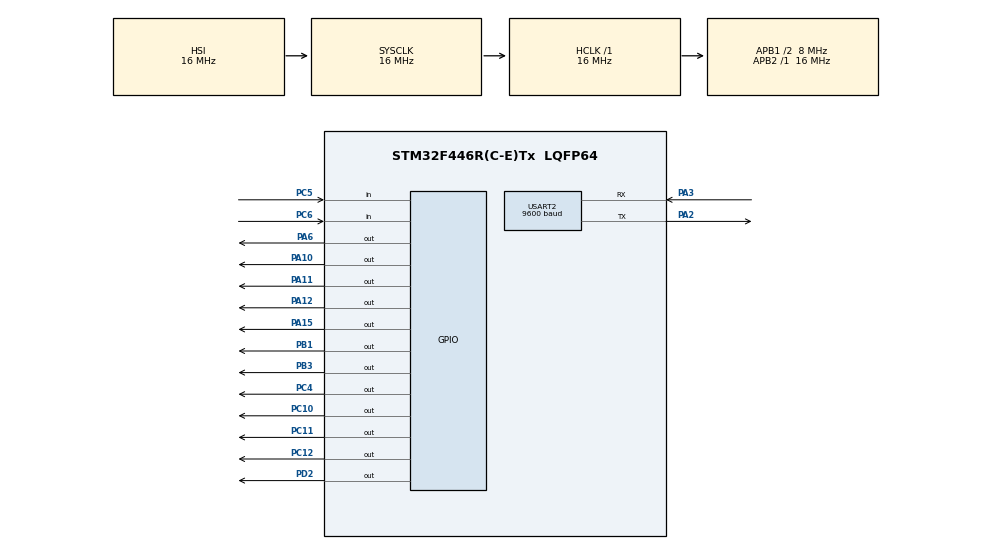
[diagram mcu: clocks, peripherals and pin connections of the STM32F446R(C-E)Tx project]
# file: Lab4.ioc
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Dma.Request0=USART2_RX
Dma.Request1=USART2_TX
Dma.USART2_RX.0.Direction=DMA_PERIPH_TO_MEMORY
Dma.USART2_RX.0.FIFOMode=DMA_FIFOMODE_DISABLE
Dma.USART2_RX.0.Instance=DMA1_Stream5
Dma.USART2_RX.0.MemDataAlignment=DMA_MDATAALIGN_BYTE
Dma.USART2_RX.0.MemInc=DMA_MINC_ENABLE
Dma.USART2_RX.0.Mode=DMA_CIRCULAR
Dma.USART2_RX.0.PeriphDataAlignment=DMA_PDATAALIGN_BYTE
Dma.USART2_RX.0.PeriphInc=DMA_PINC_DISABLE
Dma.USART2_RX.0.Priority=DMA_PRIORITY_VERY_HIGH
Dma.USART2_TX.1.Direction=DMA_MEMORY_TO_PERIPH
Dma.USART2_TX.1.FIFOMode=DMA_FIFOMODE_DISABLE
Dma.USART2_TX.1.Instance=DMA1_Stream6
Dma.USART2_TX.1.MemDataAlignment=DMA_MDATAALIGN_BYTE
Dma.USART2_TX.1.MemInc=DMA_MINC_ENABLE
Dma.USART2_TX.1.Mode=DMA_NORMAL
Dma.USART2_TX.1.PeriphDataAlignment=DMA_PDATAALIGN_BYTE
Dma.USART2_TX.1.PeriphInc=DMA_PINC_DISABLE
Dma.USART2_TX.1.Priority=DMA_PRIORITY_HIGH
Mcu.Family=STM32F4
Mcu.Name=STM32F446R(C-E)Tx
Mcu.Package=LQFP64
NVIC.DMA1_Stream5_IRQn=true\:0\:0\:false\:false\:true\:false\:true\:true
NVIC.DMA1_Stream6_IRQn=true\:0\:0\:false\:false\:true\:false\:true\:true
NVIC.PriorityGroup=NVIC_PRIORITYGROUP_4
NVIC.TIM2_IRQn=true\:0\:0\:false\:false\:true\:true\:true\:true
PA10.Signal=GPIO_Output
PA11.Signal=GPIO_Output
PA12.Signal=GPIO_Output
PA15.Signal=GPIO_Output
PA2.Mode=Asynchronous
PA2.Signal=USART2_TX
PA3.Mode=Asynchronous
PA3.Signal=USART2_RX
PA6.Signal=GPIO_Output
PB1.Signal=GPIO_Output
PB3.Signal=GPIO_Output
PC10.Signal=GPIO_Output
PC11.Signal=GPIO_Output
PC12.Signal=GPIO_Output
PC4.Signal=GPIO_Output
PC5.Signal=GPIO_Input
PC6.Signal=GPIO_Input
PD2.Signal=GPIO_Output
PH0-OSC_IN.Mode=HSE-External-Oscillator
PH0-OSC_IN.Signal=RCC_OSC_IN
PH1-OSC_OUT.Mode=HSE-External-Oscillator
PH1-OSC_OUT.Signal=RCC_OSC_OUT
ProjectManager.HeapSize=0x200
ProjectManager.StackSize=0x400
ProjectManager.TargetToolchain=STM32CubeIDE
RCC.AHBFreq_Value=16000000
RCC.APB1CLKDivider=RCC_HCLK_DIV2
RCC.APB1Freq_Value=8000000
RCC.APB1TimFreq_Value=16000000
RCC.APB2Freq_Value=16000000
RCC.APB2TimFreq_Value=16000000
RCC.CortexFreq_Value=16000000
RCC.HCLKFreq_Value=16000000
RCC.HSE_VALUE=25000000
RCC.PLLM=8
RCC.PLLN=50
RCC.SYSCLKFreq_VALUE=16000000
RCC.USBFreq_Value=50000000
RCC.VCOOutputFreq_Value=100000000
TIM2.Period=10000
TIM2.Prescaler=15
USART2.BaudRate=9600
USART2.VirtualMode=VM_ASYNC
VP_TIM2_VS_ClockSourceINT.Mode=Internal
board=custom

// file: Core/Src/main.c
/* USER CODE BEGIN Header */
/**
  ******************************************************************************
  * @file           : main.c
  * @brief          : Main program body
  ******************************************************************************
  * @attention
  *
  * Copyright (c) 2022 STMicroelectronics.
  * All rights reserved.
  *
  * This software is licensed under terms that can be found in the LICENSE file
  * in the root directory of this software component.
  * If no LICENSE file comes with this software, it is provided AS-IS.
  *
  ******************************************************************************
  */
/* USER CODE END Header */
#include "main.h"

TIM_HandleTypeDef htim2;

UART_HandleTypeDef huart2;
DMA_HandleTypeDef hdma_usart2_rx;
DMA_HandleTypeDef hdma_usart2_tx;

void SystemClock_Config(void);
static void MX_GPIO_Init(void);
static void MX_DMA_Init(void);
static void MX_USART2_UART_Init(void);
static void MX_TIM2_Init(void);

/* USER CODE BEGIN 0 */
float fcn(float x) {
	return x;
}

float buf[8] = {0};
int offset = 0;
void HAL_TIM_PeriodElapsedCallback(TIM_HandleTypeDef* htim) {
	HAL_UART_Transmit_DMA(&huart2, (uint8_t*)&buf[offset], sizeof(float));
	offset = (offset + 4) % 8;
}
/* USER CODE END 0 */

int main(void)
{

  /* MCU Configuration--------------------------------------------------------*/

  /* Reset of all peripherals, Initializes the Flash interface and the Systick. */
  HAL_Init();

  /* Configure the system clock */
  SystemClock_Config();

  /* Initialize all configured peripherals */
  MX_GPIO_Init();
  MX_DMA_Init();
  MX_USART2_UART_Init();
  MX_TIM2_Init();
  /* USER CODE BEGIN 2 */

  HAL_TIM_Base_Start_IT(&htim2);
  HAL_UART_Receive_DMA(&huart2, (uint8_t*)&buf, 8);

  /* USER CODE END 2 */

  /* Infinite loop */
  while (1)
  {

  }
}

void SystemClock_Config(void)
{
  RCC_OscInitTypeDef RCC_OscInitStruct = {0};
  RCC_ClkInitTypeDef RCC_ClkInitStruct = {0};

  /** Configure the main internal regulator output voltage
  */
  __HAL_RCC_PWR_CLK_ENABLE();
  __HAL_PWR_VOLTAGESCALING_CONFIG(PWR_REGULATOR_VOLTAGE_SCALE3);

  /** Initializes the RCC Oscillators according to the specified parameters
  * in the RCC_OscInitTypeDef structure.
  */
  RCC_OscInitStruct.OscillatorType = RCC_OSCILLATORTYPE_HSI;
  RCC_OscInitStruct.HSIState = RCC_HSI_ON;
  RCC_OscInitStruct.HSICalibrationValue = RCC_HSICALIBRATION_DEFAULT;
  RCC_OscInitStruct.PLL.PLLState = RCC_PLL_NONE;
  if (HAL_RCC_OscConfig(&RCC_OscInitStruct) != HAL_OK)
  {
    Error_Handler();
  }

  /** Initializes the CPU, AHB and APB buses clocks
  */
  RCC_ClkInitStruct.ClockType = RCC_CLOCKTYPE_HCLK|RCC_CLOCKTYPE_SYSCLK
                              |RCC_CLOCKTYPE_PCLK1|RCC_CLOCKTYPE_PCLK2;
  RCC_ClkInitStruct.SYSCLKSource = RCC_SYSCLKSOURCE_HSI;
  RCC_ClkInitStruct.AHBCLKDivider = RCC_SYSCLK_DIV1;
  RCC_ClkInitStruct.APB1CLKDivider = RCC_HCLK_DIV2;
  RCC_ClkInitStruct.APB2CLKDivider = RCC_HCLK_DIV1;

  if (HAL_RCC_ClockConfig(&RCC_ClkInitStruct, FLASH_LATENCY_0) != HAL_OK)
  {
    Error_Handler();
  }
}

static void MX_TIM2_Init(void)
{

  TIM_ClockConfigTypeDef sClockSourceConfig = {0};
  TIM_MasterConfigTypeDef sMasterConfig = {0};

  htim2.Instance = TIM2;
  htim2.Init.Prescaler = 15;
  htim2.Init.CounterMode = TIM_COUNTERMODE_UP;
  htim2.Init.Period = 10000;
  htim2.Init.ClockDivision = TIM_CLOCKDIVISION_DIV1;
  htim2.Init.AutoReloadPreload = TIM_AUTORELOAD_PRELOAD_DISABLE;
  if (HAL_TIM_Base_Init(&htim2) != HAL_OK)
  {
    Error_Handler();
  }
  sClockSourceConfig.ClockSource = TIM_CLOCKSOURCE_INTERNAL;
  if (HAL_TIM_ConfigClockSource(&htim2, &sClockSourceConfig) != HAL_OK)
  {
    Error_Handler();
  }
  sMasterConfig.MasterOutputTrigger = TIM_TRGO_RESET;
  sMasterConfig.MasterSlaveMode = TIM_MASTERSLAVEMODE_DISABLE;
  if (HAL_TIMEx_MasterConfigSynchronization(&htim2, &sMasterConfig) != HAL_OK)
  {
    Error_Handler();
  }

}

static void MX_USART2_UART_Init(void)
{

  huart2.Instance = USART2;
  huart2.Init.BaudRate = 9600;
  huart2.Init.WordLength = UART_WORDLENGTH_8B;
  huart2.Init.StopBits = UART_STOPBITS_1;
  huart2.Init.Parity = UART_PARITY_NONE;
  huart2.Init.Mode = UART_MODE_TX_RX;
  huart2.Init.HwFlowCtl = UART_HWCONTROL_NONE;
  huart2.Init.OverSampling = UART_OVERSAMPLING_16;
  if (HAL_UART_Init(&huart2) != HAL_OK)
  {
    Error_Handler();
  }

}

static void MX_DMA_Init(void)
{

  /* DMA controller clock enable */
  __HAL_RCC_DMA1_CLK_ENABLE();

  /* DMA interrupt init */
  /* DMA1_Stream5_IRQn interrupt configuration */
  HAL_NVIC_SetPriority(DMA1_Stream5_IRQn, 0, 0);
  HAL_NVIC_EnableIRQ(DMA1_Stream5_IRQn);
  /* DMA1_Stream6_IRQn interrupt configuration */
  HAL_NVIC_SetPriority(DMA1_Stream6_IRQn, 0, 0);
  HAL_NVIC_EnableIRQ(DMA1_Stream6_IRQn);

}

static void MX_GPIO_Init(void)
{
  GPIO_InitTypeDef GPIO_InitStruct = {0};

  /* GPIO Ports Clock Enable */
  __HAL_RCC_GPIOH_CLK_ENABLE();
  __HAL_RCC_GPIOA_CLK_ENABLE();
  __HAL_RCC_GPIOC_CLK_ENABLE();
  __HAL_RCC_GPIOB_CLK_ENABLE();
  __HAL_RCC_GPIOD_CLK_ENABLE();

  /*Configure GPIO pin Output Level */
  HAL_GPIO_WritePin(GPIOA, GPIO_PIN_6|GPIO_PIN_10|GPIO_PIN_11|GPIO_PIN_12
                          |GPIO_PIN_15, GPIO_PIN_RESET);

  /*Configure GPIO pin Output Level */
  HAL_GPIO_WritePin(GPIOC, GPIO_PIN_4|GPIO_PIN_10|GPIO_PIN_11|GPIO_PIN_12, GPIO_PIN_RESET);

  /*Configure GPIO pin Output Level */
  HAL_GPIO_WritePin(GPIOB, GPIO_PIN_1|GPIO_PIN_3, GPIO_PIN_RESET);

  /*Configure GPIO pin Output Level */
  HAL_GPIO_WritePin(GPIOD, GPIO_PIN_2, GPIO_PIN_RESET);

  /*Configure GPIO pins : PA6 PA10 PA11 PA12
                           PA15 */
  GPIO_InitStruct.Pin = GPIO_PIN_6|GPIO_PIN_10|GPIO_PIN_11|GPIO_PIN_12
                          |GPIO_PIN_15;
  GPIO_InitStruct.Mode = GPIO_MODE_OUTPUT_PP;
  GPIO_InitStruct.Pull = GPIO_NOPULL;
  GPIO_InitStruct.Speed = GPIO_SPEED_FREQ_LOW;
  HAL_GPIO_Init(GPIOA, &GPIO_InitStruct);

  /*Configure GPIO pins : PC4 PC10 PC11 PC12 */
  GPIO_InitStruct.Pin = GPIO_PIN_4|GPIO_PIN_10|GPIO_PIN_11|GPIO_PIN_12;
  GPIO_InitStruct.Mode = GPIO_MODE_OUTPUT_PP;
  GPIO_InitStruct.Pull = GPIO_NOPULL;
  GPIO_InitStruct.Speed = GPIO_SPEED_FREQ_LOW;
  HAL_GPIO_Init(GPIOC, &GPIO_InitStruct);

  /*Configure GPIO pins : PC5 PC6 */
  GPIO_InitStruct.Pin = GPIO_PIN_5|GPIO_PIN_6;
  GPIO_InitStruct.Mode = GPIO_MODE_INPUT;
  GPIO_InitStruct.Pull = GPIO_NOPULL;
  HAL_GPIO_Init(GPIOC, &GPIO_InitStruct);

  /*Configure GPIO pins : PB1 PB3 */
  GPIO_InitStruct.Pin = GPIO_PIN_1|GPIO_PIN_3;
  GPIO_InitStruct.Mode = GPIO_MODE_OUTPUT_PP;
  GPIO_InitStruct.Pull = GPIO_NOPULL;
  GPIO_InitStruct.Speed = GPIO_SPEED_FREQ_LOW;
  HAL_GPIO_Init(GPIOB, &GPIO_InitStruct);

  /*Configure GPIO pin : PD2 */
  GPIO_InitStruct.Pin = GPIO_PIN_2;
  GPIO_InitStruct.Mode = GPIO_MODE_OUTPUT_PP;
  GPIO_InitStruct.Pull = GPIO_NOPULL;
  GPIO_InitStruct.Speed = GPIO_SPEED_FREQ_LOW;
  HAL_GPIO_Init(GPIOD, &GPIO_InitStruct);

}

void Error_Handler(void)
{
  __disable_irq();
  while (1)
  {
  }
}
